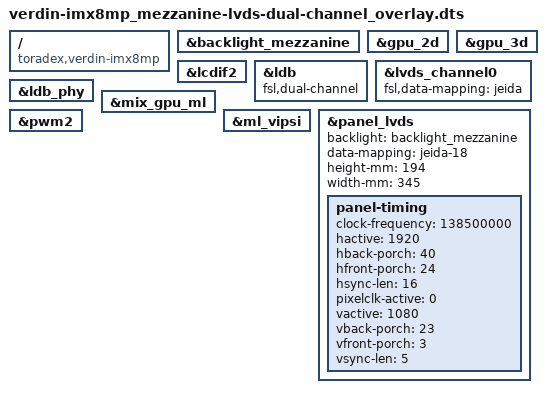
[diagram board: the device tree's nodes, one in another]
// SPDX-License-Identifier: GPL-2.0-or-later OR MIT
/*
 * Copyright 2020-2021 Toradex
 */

// Verdin iMX8M Plus Mezzanine with LG LP156WF1 dual-channel LVDS Panel

/dts-v1/;
/plugin/;

/ {
	compatible = "toradex,verdin-imx8mp";
};

&backlight_mezzanine {
	status = "okay";
};

&gpu_2d {
	status = "okay";
};

&gpu_3d {
	status = "okay";
};

&lcdif2 {
	status = "okay";
};

&ldb {
	fsl,dual-channel;
	status = "okay";
};

&lvds_channel0 {
	fsl,data-mapping = "jeida";
};

&ldb_phy {
	status = "okay";
};

&mix_gpu_ml {
	status = "okay";
};

&ml_vipsi {
	status = "okay";
};

&panel_lvds {
	backlight = <&backlight_mezzanine>;
	data-mapping = "jeida-18";
	height-mm = <194>;
	width-mm = <345>;
	status = "okay";

	panel-timing {
		clock-frequency = <138500000>;
		hactive = <1920>;
		hback-porch = <40>;
		hfront-porch = <24>;
		hsync-len = <16>;
		pixelclk-active = <0>;
		vactive = <1080>;
		vback-porch = <23>;
		vfront-porch = <3>;
		vsync-len = <5>;
	};
};

&pwm2 {
	status = "okay";
};
